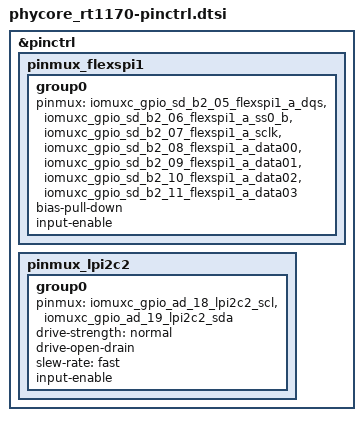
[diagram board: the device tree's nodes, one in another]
/*
 * Copyright 2024, PHYTEC America, LLC
 *
 * SPDX-License-Identifier: Apache-2.0
 */

#include <nxp/nxp_imx/rt/mimxrt1176dvmaa-pinctrl.dtsi>

&pinctrl {
	pinmux_flexspi1: pinmux_flexspi1 {
		group0 {
			pinmux = <&iomuxc_gpio_sd_b2_05_flexspi1_a_dqs>,
				<&iomuxc_gpio_sd_b2_06_flexspi1_a_ss0_b>,
				<&iomuxc_gpio_sd_b2_07_flexspi1_a_sclk>,
				<&iomuxc_gpio_sd_b2_08_flexspi1_a_data00>,
				<&iomuxc_gpio_sd_b2_09_flexspi1_a_data01>,
				<&iomuxc_gpio_sd_b2_10_flexspi1_a_data02>,
				<&iomuxc_gpio_sd_b2_11_flexspi1_a_data03>;
			bias-pull-down;
			input-enable;
		};
	};

	pinmux_lpi2c2: pinmux_lpi2c2 {
		group0 {
			pinmux = <&iomuxc_gpio_ad_18_lpi2c2_scl>,
				<&iomuxc_gpio_ad_19_lpi2c2_sda>;
			drive-strength = "normal";
			drive-open-drain;
			slew-rate = "fast";
			input-enable;
		};
	};
};
